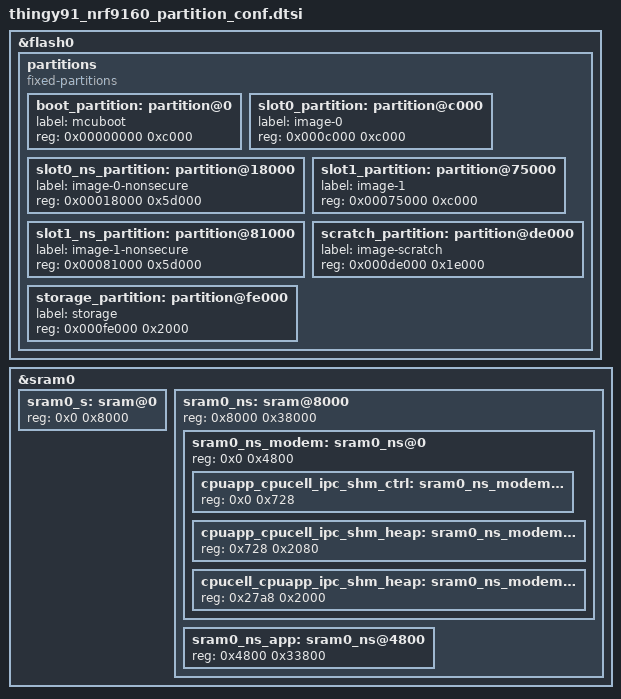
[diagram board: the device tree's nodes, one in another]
/*
 * Copyright (c) 2019 Nordic Semiconductor ASA
 *
 * SPDX-License-Identifier: LicenseRef-Nordic-5-Clause
 */

/*
 * Default Flash planning for thingy91_nrf9160.
 *
 * Zephyr build for nRF9160 with ARM TrustZone-M support,
 * implies building Secure and Non-Secure Zephyr images.
 *
 * Secure image will be placed, by default, in flash0
 * (or in slot0, if MCUboot is present).
 * Secure image will use sram0 for system memory.
 *
 * Non-Secure image will be placed in slot0_ns, and use
 * sram0_ns for system memory.
 *
 * Note that the Secure image only requires knowledge of
 * the beginning of the Non-Secure image (not its size).
 */

&flash0 {
	/*
	 * For more information, see:
	 * http://docs.zephyrproject.org/devices/dts/flash_partitions.html
	 */
	partitions {
		compatible = "fixed-partitions";
		#address-cells = <1>;
		#size-cells = <1>;

		boot_partition: partition@0 {
			label = "mcuboot";
			reg = <0x00000000 0xc000>;
		};

		slot0_partition: partition@c000 {
			label = "image-0";
			reg = <0x000c000 0xc000>;
		};

		slot0_ns_partition: partition@18000 {
			label = "image-0-nonsecure";
			reg = <0x00018000 0x5d000>;
		};

		slot1_partition: partition@75000 {
			label = "image-1";
			reg = <0x00075000 0xc000>;
		};

		slot1_ns_partition: partition@81000 {
			label = "image-1-nonsecure";
			reg = <0x00081000 0x5d000>;
		};

		scratch_partition: partition@de000 {
			label = "image-scratch";
			reg = <0x000de000 0x1e000>;
		};

		/* Empty 0x000fc000 -> 0x000fe000 */

		storage_partition: partition@fe000 {
			label = "storage";
			reg = <0x000fe000 0x2000>;
		};
	};
};

/* Default SRAM planning when building for nRF9160 with
 * ARM TrustZone-M support
 * - Lowest 32 kB SRAM allocated to Secure image (sram0_s).
 * - 18 kB SRAM reserved for and used by the modem library (sram0_ns_modem).
 * - Upper 206 kB allocated to Non-Secure image (sram0_ns_app).
 */

&sram0 {
	sram0_s: sram@0 {
		/* Secure image memory */
		reg = <0x0 0x8000>;
	};

	sram0_ns: sram@8000 {
		/* Non-Secure image memory */
		reg = <0x8000 0x38000>;
		#address-cells = <1>;
		#size-cells = <1>;
		ranges = <0x0 0x8000 0x38000>;

		sram0_ns_modem: sram0_ns@0 {
			/* Modem (shared) memory */
			reg = <0x0 0x4800>;
			#address-cells = <1>;
			#size-cells = <1>;
			ranges = <0x0 0x0 0x4800>;

			cpuapp_cpucell_ipc_shm_ctrl: sram0_ns_modem@0 {
				/* Modem IPC control */
				reg = <0x0 0x728>;
			};

			cpuapp_cpucell_ipc_shm_heap: sram0_ns_modem@728 {
				/* Modem IPC transmit */
				reg = <0x728 0x2080>;
			};

			cpucell_cpuapp_ipc_shm_heap: sram0_ns_modem@27a8 {
				/* Modem IPC receive */
				reg = <0x27a8 0x2000>;
			};
		};

		sram0_ns_app: sram0_ns@4800 {
			/* Non-Secure application memory */
			reg = <0x4800 0x33800>;
		};
	};
};
